# trng_revc register map
Registers are read-only, no defined reset value unless marked. A register's access mark holds for its fields unless they carry their own. Offsets are from the block's base; lines under a group give offsets from that group; [hi:lo] are bit positions; {n}, {i} and the like mark numbered series; 'fields as' and 'values as' point back to an identical list; <NAME> marks a mode.

## Memory map
0x4004D000 TRNG size 0x1000 — Random Number Generator.

## Interrupts
4 TRNG — TRNG interrupt.

## TRNG — Random Number Generator.
Base 0x4004D000
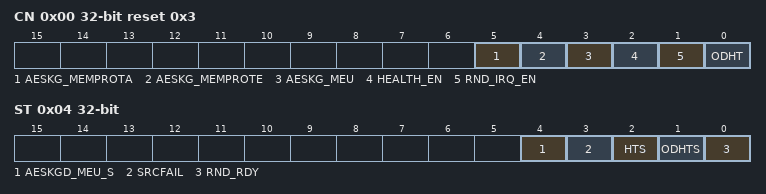
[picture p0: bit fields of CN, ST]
0x00 CN access not given reset 0x3 — TRNG Control Register.
  [5] AESKG_MEMPROTA — AES Key Generate. When enabled, the key for securing NVSRAM is generated and transferred to the secure key register automatically without user visibility or intervention. This bit is cleared by hardware once the key has been transferred to the secure key register.
  [4] AESKG_MEMPROTE — AES Key Generate. When enabled, the key for securing NVSRAM is generated and transferred to the secure key register automatically without user visibility or intervention. This bit is cleared by hardware once the key has been transferred to the secure key register.
  [3] AESKG_MEU — AES Key Generate. When enabled, the key for securing NVSRAM is generated and transferred to the secure key register automatically without user visibility or intervention. This bit is cleared by hardware once the key has been transferred to the secure key register.
  [2] HEALTH_EN ro — To enable IRQ generation when a health test fails
    0=disable; 1=enable
  [1] RND_IRQ_EN — To enable IRQ generation when a new 32-bit Random number is ready.
    0=disable; 1=enable
  [0] ODHT — Start On-Demand health test
0x04 ST — Data. The content of this register is valid only when RNG_IS = 1. When TRNG is disabled, read returns 0x0000 0000.
  [4] AESKGD_MEU_S — Automatically AES transfer on going
  [3] SRCFAIL — Entropy source has failed. IRQ is generated if HEALTH_EN=1. Write 1 to clear this bit.
    0=Works (Entopy source works correctly); 1=Fail (Entropy Source has failed)
  [2] HTS — Health test status. This bit shall be read when On-demand health test is completed (ODHTS=0) to check the result. This bit is also set when a continuous health test reports an error, IRQ is generated if HEALTH_EN=1. Write 1 to clear this bit.
    0=Pass; 1=Fail
  [1] ODHTS — On-Demand health test status
    0=Done (On demand health test done); 1=Busy (On demand health test on going)
  [0] RND_RDY — 32-bit random data is ready to read from TRNG_DATA register. Reading TRNG_DATA when RND_RDY=0 will return all 0's. IRQ is generated when RND_RDY=1 if TRNG_CN.RND_IRQ_EN=1.
    0=Busy (TRNG Busy); 1=Ready (32 bit random data is ready)
0x08 DATA — Data. The content of this register is valid only when RNG_IS = 1. When TRNG is disabled, read returns 0x0000 0000.
  [31:0] DATA — Data. The content of this register is valid only when RNG_IS =1. When TNRG is disabled, read returns 0x0000 0000.
